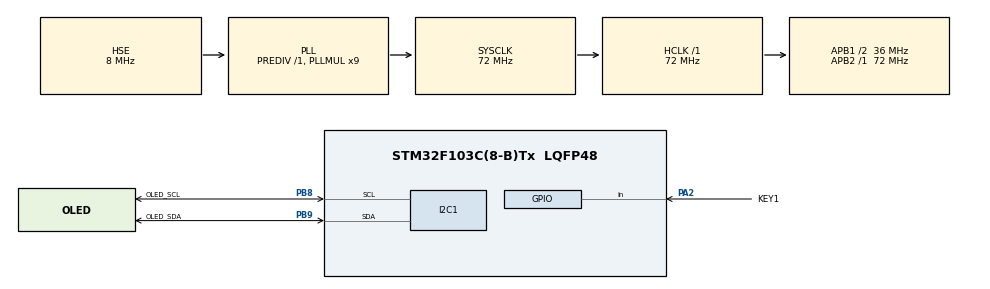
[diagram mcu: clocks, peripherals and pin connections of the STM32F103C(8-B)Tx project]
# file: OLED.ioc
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Mcu.Family=STM32F1
Mcu.Name=STM32F103C(8-B)Tx
Mcu.Package=LQFP48
NVIC.PriorityGroup=NVIC_PRIORITYGROUP_4
PA0-WKUP.Mode=SYS_WakeUp0
PA0-WKUP.Signal=SYS_WKUP
PA13.Mode=Serial_Wire
PA13.Signal=SYS_JTMS-SWDIO
PA14.Mode=Serial_Wire
PA14.Signal=SYS_JTCK-SWCLK
PA2.GPIO_Label=KEY1
PA2.GPIO_PuPd=GPIO_PULLUP
PA2.Signal=GPIO_Input
PB8.GPIO_Label=OLED_SCL
PB8.Mode=I2C
PB8.Signal=I2C1_SCL
PB9.GPIO_Label=OLED_SDA
PB9.Mode=I2C
PB9.Signal=I2C1_SDA
PD0-OSC_IN.Mode=HSE-External-Oscillator
PD0-OSC_IN.Signal=RCC_OSC_IN
PD1-OSC_OUT.Mode=HSE-External-Oscillator
PD1-OSC_OUT.Signal=RCC_OSC_OUT
ProjectManager.HeapSize=0x200
ProjectManager.StackSize=0x400
ProjectManager.TargetToolchain=MDK-ARM V5
RCC.AHBFreq_Value=72000000
RCC.APB1CLKDivider=RCC_HCLK_DIV2
RCC.APB1Freq_Value=36000000
RCC.APB1TimFreq_Value=72000000
RCC.APB2Freq_Value=72000000
RCC.APB2TimFreq_Value=72000000
RCC.HCLKFreq_Value=72000000
RCC.PLLMUL=RCC_PLL_MUL9
RCC.PLLSourceVirtual=RCC_PLLSOURCE_HSE
RCC.SYSCLKFreq_VALUE=72000000
RCC.SYSCLKSource=RCC_SYSCLKSOURCE_PLLCLK
RCC.USBFreq_Value=72000000
board=custom

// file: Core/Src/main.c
/* USER CODE BEGIN Header */
/**
  ******************************************************************************
  * @file           : main.c
  * @brief          : Main program body
  ******************************************************************************
  * @attention
  *
  * Copyright (c) 2026 STMicroelectronics.
  * All rights reserved.
  *
  * This software is licensed under terms that can be found in the LICENSE file
  * in the root directory of this software component.
  * If no LICENSE file comes with this software, it is provided AS-IS.
  *
  ******************************************************************************
  */
/* USER CODE END Header */
#include "main.h"
#include "i2c.h"
#include "gpio.h"

/* USER CODE BEGIN Includes */
#include "../../../OLED/Drivers/OLED/OLED.h"
/* USER CODE END Includes */

void SystemClock_Config(void);

int main(void)
{

  /* MCU Configuration--------------------------------------------------------*/

  /* Reset of all peripherals, Initializes the Flash interface and the Systick. */
  HAL_Init();

  /* Configure the system clock */
  SystemClock_Config();

  /* Initialize all configured peripherals */
  MX_GPIO_Init();
  MX_I2C1_Init();
  /* USER CODE BEGIN 2 */
  OLED_Init();
  OLED_Clear();
  /* USER CODE END 2 */

  /* Infinite loop */
  /* USER CODE BEGIN WHILE */
  while (1)
  {
	  OLED_Clear();

	  OLED_ShowCHinese(0,0,0,0);
	  OLED_ShowCHinese(16,0,1,0);
	  OLED_ShowCHinese(32,0,2,0);
	  OLED_ShowCHinese(48,0,3,0);
	  OLED_ShowCHinese(64,0,4,0);
	  OLED_ShowCHinese(80,0,5,0);
	  OLED_ShowCHinese(96,0,6,0);

	  HAL_Delay(2000);

	  OLED_Clear();

	  /*第一行*/
	  OLED_ShowString(0,0,"OLED",16,0);
	  OLED_ShowCHinese(32,0,7,0);
	  OLED_ShowCHinese(48,0,8,0);
	  OLED_ShowCHinese(64,0,9,0);
	  OLED_ShowCHinese(80,0,10,0);

	  /*第二行*/
	  OLED_ShowCHinese(0,3,11,0);
	  OLED_ShowCHinese(16,3,12,0);
	  OLED_ShowString(32,3,"A2361",16,0);
	  // 修改为显示“宇”，索引 17（字库末尾）
	  OLED_ShowCHinese(80,3,17,0);   // 原依次显示乐、正、徵、徵，现改为一个“宇”

	  /*第三行*/
	  OLED_ShowString(0,6,"2026.4.27",16,0);

	  HAL_Delay(5000);
	  OLED_Clear();

    /* USER CODE END WHILE */

  }
}

void SystemClock_Config(void)
{
  RCC_OscInitTypeDef RCC_OscInitStruct = {0};
  RCC_ClkInitTypeDef RCC_ClkInitStruct = {0};

  /** Initializes the RCC Oscillators according to the specified parameters
  * in the RCC_OscInitTypeDef structure.
  */
  RCC_OscInitStruct.OscillatorType = RCC_OSCILLATORTYPE_HSE;
  RCC_OscInitStruct.HSEState = RCC_HSE_ON;
  RCC_OscInitStruct.HSEPredivValue = RCC_HSE_PREDIV_DIV1;
  RCC_OscInitStruct.HSIState = RCC_HSI_ON;
  RCC_OscInitStruct.PLL.PLLState = RCC_PLL_ON;
  RCC_OscInitStruct.PLL.PLLSource = RCC_PLLSOURCE_HSE;
  RCC_OscInitStruct.PLL.PLLMUL = RCC_PLL_MUL9;
  if (HAL_RCC_OscConfig(&RCC_OscInitStruct) != HAL_OK)
  {
    Error_Handler();
  }

  /** Initializes the CPU, AHB and APB buses clocks
  */
  RCC_ClkInitStruct.ClockType = RCC_CLOCKTYPE_HCLK|RCC_CLOCKTYPE_SYSCLK
                              |RCC_CLOCKTYPE_PCLK1|RCC_CLOCKTYPE_PCLK2;
  RCC_ClkInitStruct.SYSCLKSource = RCC_SYSCLKSOURCE_PLLCLK;
  RCC_ClkInitStruct.AHBCLKDivider = RCC_SYSCLK_DIV1;
  RCC_ClkInitStruct.APB1CLKDivider = RCC_HCLK_DIV2;
  RCC_ClkInitStruct.APB2CLKDivider = RCC_HCLK_DIV1;

  if (HAL_RCC_ClockConfig(&RCC_ClkInitStruct, FLASH_LATENCY_2) != HAL_OK)
  {
    Error_Handler();
  }
}

void Error_Handler(void)
{
  __disable_irq();
  while (1)
  {
  }
}
